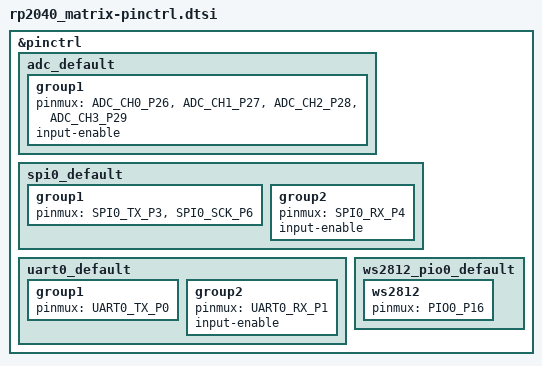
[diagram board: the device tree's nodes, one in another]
/*
 * Copyright (c) 2024 Jonas Berg
 *
 * SPDX-License-Identifier: Apache-2.0
 */

#include <dt-bindings/pinctrl/rpi-pico-rp2040-pinctrl.h>

&pinctrl {

	adc_default: adc_default {
		group1 {
			pinmux = <ADC_CH0_P26>, <ADC_CH1_P27>, <ADC_CH2_P28>, <ADC_CH3_P29>;
			input-enable;
		};
	};

	spi0_default: spi0_default {
		group1 {
			pinmux = <SPI0_TX_P3>, <SPI0_SCK_P6>;
		};

		group2 {
			pinmux = <SPI0_RX_P4>;
			input-enable;
		};
	};

	uart0_default: uart0_default {
		group1 {
			pinmux = <UART0_TX_P0>;
		};

		group2 {
			pinmux = <UART0_RX_P1>;
			input-enable;
		};
	};

	ws2812_pio0_default: ws2812_pio0_default {
		ws2812 {
			pinmux = <PIO0_P16>;
		};
	};
};
